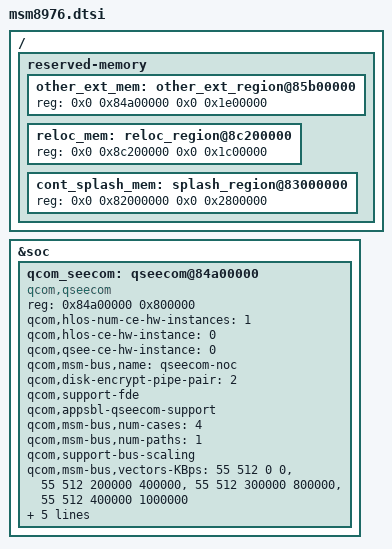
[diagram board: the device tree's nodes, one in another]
/*
 * Copyright (c) 2014-2016, The Linux Foundation. All rights reserved.
 *
 * This program is free software; you can redistribute it and/or modify
 * it under the terms of the GNU General Public License version 2 and
 * only version 2 as published by the Free Software Foundation.
 *
 * This program is distributed in the hope that it will be useful,
 * but WITHOUT ANY WARRANTY; without even the implied warranty of
 * MERCHANTABILITY or FITNESS FOR A PARTICULAR PURPOSE.  See the
 * GNU General Public License for more details.
 */

/ {
	reserved-memory {
		other_ext_mem: other_ext_region@85b00000 {
			reg = <0x0 0x84a00000 0x0 0x1e00000>;
		};

		reloc_mem: reloc_region@8c200000 {
			reg = <0x0 0x8c200000 0x0 0x1c00000>;
		};

		cont_splash_mem: splash_region@83000000 {
			reg = <0x0 0x82000000 0x0 0x2800000>;
		};
	};
};

&soc {
	/delete-node/ qseecom@85b00000;
	qcom_seecom: qseecom@84a00000 {
		compatible = "qcom,qseecom";
		reg = <0x84a00000 0x800000>;
		reg-names = "secapp-region";
		qcom,hlos-num-ce-hw-instances = <1>;
		qcom,hlos-ce-hw-instance = <0>;
		qcom,qsee-ce-hw-instance = <0>;
		qcom,msm-bus,name = "qseecom-noc";
		qcom,disk-encrypt-pipe-pair = <2>;
		qcom,support-fde;
		qcom,appsbl-qseecom-support;
		qcom,msm-bus,num-cases = <4>;
		qcom,msm-bus,num-paths = <1>;
		qcom,support-bus-scaling;
		qcom,msm-bus,vectors-KBps =
			<55 512 0 0>,
			<55 512 200000 400000>,
			<55 512 300000 800000>,
			<55 512 400000 1000000>;
		clocks = <&clock_gcc clk_crypto_clk_src>,
			 <&clock_gcc clk_gcc_crypto_clk>,
			 <&clock_gcc clk_gcc_crypto_ahb_clk>,
			 <&clock_gcc clk_gcc_crypto_axi_clk>;
		clock-names = "core_clk_src", "core_clk",
				"iface_clk", "bus_clk";
		qcom,ce-opp-freq = <100000000>;
	};
};
